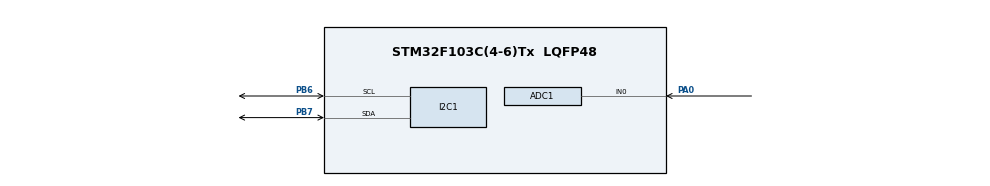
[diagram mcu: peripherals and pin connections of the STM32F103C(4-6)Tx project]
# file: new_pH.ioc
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ADC1.Channel-0\#ChannelRegularConversion=ADC_CHANNEL_0
ADC1.EnableAnalogWatchDog=false
ADC1.NbrOfConversionFlag=1
ADC1.Rank-0\#ChannelRegularConversion=1
ADC1.SamplingTime-0\#ChannelRegularConversion=ADC_SAMPLETIME_1CYCLE_5
ADC1.master=1
Mcu.Family=STM32F1
Mcu.Name=STM32F103C(4-6)Tx
Mcu.Package=LQFP48
NVIC.PriorityGroup=NVIC_PRIORITYGROUP_4
PA0-WKUP.Signal=ADCx_IN0
PA13.Mode=Serial_Wire
PA13.Signal=SYS_JTMS-SWDIO
PA14.Mode=Serial_Wire
PA14.Signal=SYS_JTCK-SWCLK
PB6.Mode=I2C
PB6.Signal=I2C1_SCL
PB7.Mode=I2C
PB7.Signal=I2C1_SDA
ProjectManager.HeapSize=0x200
ProjectManager.StackSize=0x400
ProjectManager.TargetToolchain=STM32CubeIDE
RCC.APB1Freq_Value=8000000
RCC.APB2Freq_Value=8000000
SH.ADCx_IN0.0=ADC1_IN0,IN0
board=custom

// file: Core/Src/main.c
/* USER CODE BEGIN Header */
/**
  ******************************************************************************
  * @file           : main.c
  * @brief          : Main program body
  ******************************************************************************
  * @attention
  *
  * Copyright (c) 2025 STMicroelectronics.
  * All rights reserved.
  *
  * This software is licensed under terms that can be found in the LICENSE file
  * in the root directory of this software component.
  * If no LICENSE file comes with this software, it is provided AS-IS.
  *
  ******************************************************************************
  */
/* USER CODE END Header */
#include "main.h"

/* USER CODE BEGIN Includes */
#include <stdlib.h>
/* USER CODE END Includes */

/* USER CODE BEGIN PTD */
#define NUM_SAMPLES 10   // How many samples to take for an average reading
#define VREF 3.3f        // STM32's reference voltage
#define R1_OHMS 10000.0f // The value of first resistor (R1)
#define R2_OHMS 10000.0f // The value of second resistor (R2)
/* USER CODE END PTD */

ADC_HandleTypeDef hadc1;

I2C_HandleTypeDef hi2c1;

void SystemClock_Config(void);
static void MX_GPIO_Init(void);
static void MX_ADC1_Init(void);
static void MX_I2C1_Init(void);

/* USER CODE BEGIN 0 */
uint32_t adc_val;
float calibration_offset = 21.84 ;
uint32_t adc_buffer[NUM_SAMPLES];
float sensor_voltage=0.0f;
float ph_value = 0.0f;
int compare_uint32(const void *a, const void *b) {
    uint32_t arg1 = *(const uint32_t*)a;
    uint32_t arg2 = *(const uint32_t*)b;
    if (arg1 < arg2) return -1;
    if (arg1 > arg2) return 1;
    return 0;
}
/* USER CODE END 0 */

int main(void)
{

  /* MCU Configuration--------------------------------------------------------*/

  /* Reset of all peripherals, Initializes the Flash interface and the Systick. */
  HAL_Init();

  /* Configure the system clock */
  SystemClock_Config();

  /* Initialize all configured peripherals */
  MX_GPIO_Init();
  MX_ADC1_Init();
  MX_I2C1_Init();

  /* Infinite loop */
  /* USER CODE BEGIN WHILE */
  while (1)
  {
	  // 1. Take multiple samples to get a stable reading
	    for(int i = 0; i < NUM_SAMPLES; i++) {
	      HAL_ADC_Start(&hadc1);
	      if (HAL_ADC_PollForConversion(&hadc1, 100) == HAL_OK) {
	          adc_buffer[i] = HAL_ADC_GetValue(&hadc1);
	      }
	      HAL_ADC_Stop(&hadc1);
	      HAL_Delay(30);
	    }

	    // 2. Sort the array to discard the highest and lowest (noisy) readings
	    qsort(adc_buffer, NUM_SAMPLES, sizeof(uint32_t), compare_uint32);

	    // 3. Average the middle 6 samples for a stable result
	    unsigned long int avg_adc_val = 0;
	    for(int i = 2; i < (NUM_SAMPLES - 2); i++) {
	      avg_adc_val += adc_buffer[i];
	    }
	    float avg_adc_float = (float)avg_adc_val / (NUM_SAMPLES - 4);

	    // 4. Convert the average ADC reading back to the ORIGINAL sensor voltage
	    // First, calculate the voltage seen at the STM32 pin
	    float voltage_at_pin = avg_adc_float * (VREF / 4095.0f);

	    // Second, reverse the voltage divider calculation to find the sensor's true output voltage
	    sensor_voltage = voltage_at_pin * (R1_OHMS + R2_OHMS) / R2_OHMS;

	    // 5. Convert the sensor voltage to a pH value using the formula
	    // The formula is: pH = (slope * voltage) + offset
	    ph_value = -5.70 * sensor_voltage + calibration_offset;

	    // Wait for a second before the next reading cycle
	    HAL_Delay(1000);
    /* USER CODE END WHILE */
	  /*
	  HAL_ADC_Start(&hadc1);
	  if (HAL_ADC_PollForConversion(&hadc1, 100) == HAL_OK) {
	      adc_val = HAL_ADC_GetValue(&hadc1);//1551
	  }
	  HAL_ADC_Stop(&hadc1);
	  HAL_Delay(500);
	  */
  }
}

void SystemClock_Config(void)
{
  RCC_OscInitTypeDef RCC_OscInitStruct = {0};
  RCC_ClkInitTypeDef RCC_ClkInitStruct = {0};
  RCC_PeriphCLKInitTypeDef PeriphClkInit = {0};

  /** Initializes the RCC Oscillators according to the specified parameters
  * in the RCC_OscInitTypeDef structure.
  */
  RCC_OscInitStruct.OscillatorType = RCC_OSCILLATORTYPE_HSI;
  RCC_OscInitStruct.HSIState = RCC_HSI_ON;
  RCC_OscInitStruct.HSICalibrationValue = RCC_HSICALIBRATION_DEFAULT;
  RCC_OscInitStruct.PLL.PLLState = RCC_PLL_NONE;
  if (HAL_RCC_OscConfig(&RCC_OscInitStruct) != HAL_OK)
  {
    Error_Handler();
  }

  /** Initializes the CPU, AHB and APB buses clocks
  */
  RCC_ClkInitStruct.ClockType = RCC_CLOCKTYPE_HCLK|RCC_CLOCKTYPE_SYSCLK
                              |RCC_CLOCKTYPE_PCLK1|RCC_CLOCKTYPE_PCLK2;
  RCC_ClkInitStruct.SYSCLKSource = RCC_SYSCLKSOURCE_HSI;
  RCC_ClkInitStruct.AHBCLKDivider = RCC_SYSCLK_DIV1;
  RCC_ClkInitStruct.APB1CLKDivider = RCC_HCLK_DIV1;
  RCC_ClkInitStruct.APB2CLKDivider = RCC_HCLK_DIV1;

  if (HAL_RCC_ClockConfig(&RCC_ClkInitStruct, FLASH_LATENCY_0) != HAL_OK)
  {
    Error_Handler();
  }
  PeriphClkInit.PeriphClockSelection = RCC_PERIPHCLK_ADC;
  PeriphClkInit.AdcClockSelection = RCC_ADCPCLK2_DIV2;
  if (HAL_RCCEx_PeriphCLKConfig(&PeriphClkInit) != HAL_OK)
  {
    Error_Handler();
  }
}

static void MX_ADC1_Init(void)
{

  ADC_ChannelConfTypeDef sConfig = {0};

  /** Common config
  */
  hadc1.Instance = ADC1;
  hadc1.Init.ScanConvMode = ADC_SCAN_DISABLE;
  hadc1.Init.ContinuousConvMode = DISABLE;
  hadc1.Init.DiscontinuousConvMode = DISABLE;
  hadc1.Init.ExternalTrigConv = ADC_SOFTWARE_START;
  hadc1.Init.DataAlign = ADC_DATAALIGN_RIGHT;
  hadc1.Init.NbrOfConversion = 1;
  if (HAL_ADC_Init(&hadc1) != HAL_OK)
  {
    Error_Handler();
  }

  /** Configure Regular Channel
  */
  sConfig.Channel = ADC_CHANNEL_0;
  sConfig.Rank = ADC_REGULAR_RANK_1;
  sConfig.SamplingTime = ADC_SAMPLETIME_1CYCLE_5;
  if (HAL_ADC_ConfigChannel(&hadc1, &sConfig) != HAL_OK)
  {
    Error_Handler();
  }

}

static void MX_I2C1_Init(void)
{

  hi2c1.Instance = I2C1;
  hi2c1.Init.ClockSpeed = 100000;
  hi2c1.Init.DutyCycle = I2C_DUTYCYCLE_2;
  hi2c1.Init.OwnAddress1 = 0;
  hi2c1.Init.AddressingMode = I2C_ADDRESSINGMODE_7BIT;
  hi2c1.Init.DualAddressMode = I2C_DUALADDRESS_DISABLE;
  hi2c1.Init.OwnAddress2 = 0;
  hi2c1.Init.GeneralCallMode = I2C_GENERALCALL_DISABLE;
  hi2c1.Init.NoStretchMode = I2C_NOSTRETCH_DISABLE;
  if (HAL_I2C_Init(&hi2c1) != HAL_OK)
  {
    Error_Handler();
  }

}

static void MX_GPIO_Init(void)
{

  /* GPIO Ports Clock Enable */
  __HAL_RCC_GPIOA_CLK_ENABLE();
  __HAL_RCC_GPIOB_CLK_ENABLE();

}

void Error_Handler(void)
{
  __disable_irq();
  while (1)
  {
  }
}
